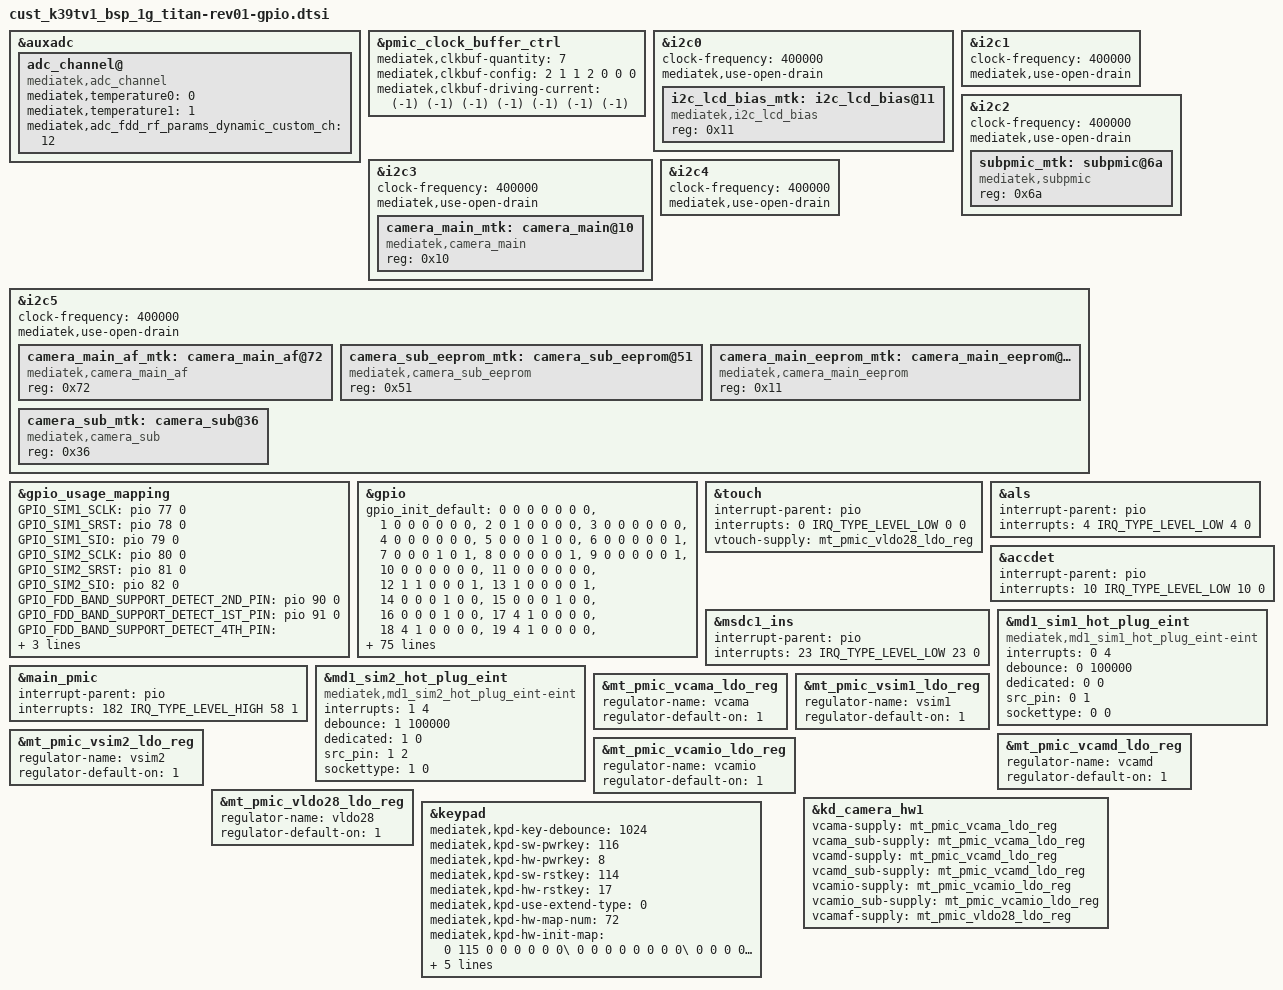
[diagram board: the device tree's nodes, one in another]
/*
 *Copyright (C) 2019 MediaTek Inc.
 *
 *This program is free software: you can redistribute it and/or modify
 *it under the terms of the GNU General Public License version 2 as
 *published by the Free Software Foundation.
 *
 *This program is distributed in the hope that it will be useful,
 *but WITHOUT ANY WARRANTY; without even the implied warranty of
 *MERCHANTABILITY or FITNESS FOR A PARTICULAR PURPOSE. See the
 *GNU General Public License for more details.
 *
 *You should have received a copy of the GNU General Public License
 *along with this program.
 *If not, see <http://www.gnu.org/licenses/>.
 */

/*
 * Generated by MTK SP DrvGen Version: 3.5.160809 for MT6739.
 * 2020-03-31 12:44:13
 * Do Not Modify The File.
 */
/*************************
 * ADC DTSI File
 *************************/

&auxadc {
	adc_channel@ {
		compatible = "mediatek,adc_channel";
		mediatek,temperature0 = <0>;
		mediatek,temperature1 = <1>;
		mediatek,adc_fdd_rf_params_dynamic_custom_ch = <12>;
		status = "okay";
	};
};


/*************************
 * CLK_BUF DTSI File
 *************************/

&pmic_clock_buffer_ctrl {
	mediatek,clkbuf-quantity = <7>;
	mediatek,clkbuf-config = <2 1 1 2 0 0 0>;
	mediatek,clkbuf-driving-current = <(-1) (-1) (-1) (-1) (-1) (-1) (-1)>;
	status = "okay";
};


/*************************
 * I2C DTSI File
 *************************/

&i2c0 {
	#address-cells = <1>;
	#size-cells = <0>;
	clock-frequency = <400000>;
	mediatek,use-open-drain;
	i2c_lcd_bias_mtk:i2c_lcd_bias@11 {
		compatible = "mediatek,i2c_lcd_bias";
		reg = <0x11>;
		status = "okay";
	};

};

&i2c1 {
	#address-cells = <1>;
	#size-cells = <0>;
	clock-frequency = <400000>;
	mediatek,use-open-drain;
};

&i2c2 {
	#address-cells = <1>;
	#size-cells = <0>;
	clock-frequency = <400000>;
	mediatek,use-open-drain;
	subpmic_mtk:subpmic@6a {
		compatible = "mediatek,subpmic";
		reg = <0x6a>;
		status = "okay";
	};

};

&i2c3 {
	#address-cells = <1>;
	#size-cells = <0>;
	clock-frequency = <400000>;
	mediatek,use-open-drain;
	camera_main_mtk:camera_main@10 {
		compatible = "mediatek,camera_main";
		reg = <0x10>;
		status = "okay";
	};

};

&i2c4 {
	#address-cells = <1>;
	#size-cells = <0>;
	clock-frequency = <400000>;
	mediatek,use-open-drain;
};

&i2c5 {
	#address-cells = <1>;
	#size-cells = <0>;
	clock-frequency = <400000>;
	mediatek,use-open-drain;
	camera_main_af_mtk:camera_main_af@72 {
		compatible = "mediatek,camera_main_af";
		reg = <0x72>;
		status = "okay";
	};

	camera_sub_eeprom_mtk:camera_sub_eeprom@51 {
		compatible = "mediatek,camera_sub_eeprom";
		reg = <0x51>;
		status = "okay";
	};

	camera_main_eeprom_mtk:camera_main_eeprom@11 {
		compatible = "mediatek,camera_main_eeprom";
		reg = <0x11>;
		status = "okay";
	};

	camera_sub_mtk:camera_sub@36 {
		compatible = "mediatek,camera_sub";
		reg = <0x36>;
		status = "okay";
	};

};



/*************************
 * GPIO DTSI File
 *************************/

&gpio_usage_mapping {
	GPIO_SIM1_SCLK = <&pio 77 0>;
	GPIO_SIM1_SRST = <&pio 78 0>;
	GPIO_SIM1_SIO = <&pio 79 0>;
	GPIO_SIM2_SCLK = <&pio 80 0>;
	GPIO_SIM2_SRST = <&pio 81 0>;
	GPIO_SIM2_SIO = <&pio 82 0>;
	GPIO_FDD_BAND_SUPPORT_DETECT_2ND_PIN = <&pio 90 0>;
	GPIO_FDD_BAND_SUPPORT_DETECT_1ST_PIN = <&pio 91 0>;
	GPIO_FDD_BAND_SUPPORT_DETECT_4TH_PIN = <&pio 108 0>;
	GPIO_FDD_BAND_SUPPORT_DETECT_3RD_PIN = <&pio 112 0>;
};

&gpio{
	gpio_init_default = <0 0 0 0 0 0 0>,
		<1 0 0 0 0 0 0>,
		<2 0 1 0 0 0 0>,
		<3 0 0 0 0 0 0>,
		<4 0 0 0 0 0 0>,
		<5 0 0 0 1 0 0>,
		<6 0 0 0 0 0 1>,
		<7 0 0 0 1 0 1>,
		<8 0 0 0 0 0 1>,
		<9 0 0 0 0 0 1>,
		<10 0 0 0 0 0 0>,
		<11 0 0 0 0 0 0>,
		<12 1 1 0 0 0 1>,
		<13 1 0 0 0 0 1>,
		<14 0 0 0 1 0 0>,
		<15 0 0 0 1 0 0>,
		<16 0 0 0 1 0 0>,
		<17 4 1 0 0 0 0>,
		<18 4 1 0 0 0 0>,
		<19 4 1 0 0 0 0>,
		<20 1 0 0 1 1 0>,
		<21 1 0 0 1 0 0>,
		<22 0 0 0 1 0 0>,
		<23 0 0 0 0 0 0>,
		<24 1 1 0 1 0 0>,
		<25 0 1 0 0 0 0>,
		<26 0 1 0 0 0 0>,
		<27 0 1 0 1 1 0>,
		<28 0 0 0 0 0 0>,
		<29 0 1 0 0 0 0>,
		<30 0 1 0 0 0 0>,
		<31 1 0 0 1 0 0>,
		<32 1 0 0 1 0 0>,
		<33 1 0 0 1 0 0>,
		<34 1 0 0 1 0 0>,
		<35 4 0 0 0 0 0>,
		<36 0 0 0 0 0 0>,
		<37 0 0 0 0 0 0>,
		<38 1 0 0 1 1 1>,
		<39 1 0 0 1 0 1>,
		<40 1 1 0 1 0 1>,
		<41 1 0 0 1 1 1>,
		<42 1 0 0 1 1 1>,
		<43 1 0 0 1 1 1>,
		<44 1 0 0 1 1 1>,
		<45 1 0 0 1 1 1>,
		<46 1 0 0 1 1 1>,
		<47 1 0 0 1 1 1>,
		<48 1 0 0 1 1 1>,
		<49 1 1 0 1 1 0>,
		<50 0 0 0 1 0 0>,
		<51 0 0 0 1 0 0>,
		<52 0 0 0 1 0 0>,
		<53 0 0 0 1 0 0>,
		<54 0 0 0 1 0 0>,
		<55 1 1 0 1 0 0>,
		<56 1 1 0 1 0 0>,
		<57 1 1 0 1 0 0>,
		<58 1 0 0 1 0 0>,
		<59 1 1 0 1 0 0>,
		<60 1 1 0 1 0 0>,
		<61 1 1 0 1 0 0>,
		<62 1 1 0 1 0 0>,
		<63 1 1 0 1 0 0>,
		<64 1 1 0 1 0 0>,
		<65 1 1 0 1 0 0>,
		<66 1 0 0 1 0 0>,
		<67 1 0 0 1 0 0>,
		<68 1 0 0 1 0 0>,
		<69 1 0 0 1 0 0>,
		<70 1 0 0 1 0 1>,
		<71 1 1 0 1 1 1>,
		<72 1 1 0 1 0 1>,
		<73 1 0 0 1 1 1>,
		<74 1 0 0 1 1 1>,
		<75 1 0 0 1 1 1>,
		<76 1 0 0 1 1 1>,
		<77 1 1 0 1 0 0>,
		<78 1 1 0 1 0 0>,
		<79 1 0 0 1 1 0>,
		<80 1 1 0 1 0 0>,
		<81 1 1 0 1 0 0>,
		<82 1 0 0 1 1 0>,
		<83 1 1 0 1 0 0>,
		<84 0 0 0 1 0 0>,
		<85 0 0 0 1 0 0>,
		<86 0 0 0 1 0 0>,
		<87 0 0 0 1 0 0>,
		<88 1 0 0 1 0 0>,
		<89 1 0 0 1 0 0>,
		<90 0 0 0 1 0 0>,
		<91 0 0 0 1 0 0>,
		<92 1 1 0 1 0 0>,
		<93 1 1 0 1 0 0>,
		<94 0 0 0 0 0 0>,
		<95 1 0 0 0 0 0>,
		<96 0 1 0 0 0 0>,
		<97 1 1 0 1 0 0>,
		<98 1 1 0 1 0 0>,
		<99 0 0 0 1 0 0>,
		<100 1 1 0 1 0 0>,
		<101 1 1 0 1 0 0>,
		<102 1 1 0 1 0 0>,
		<103 0 0 0 1 0 0>,
		<104 0 0 0 1 0 0>,
		<105 1 1 0 1 0 0>,
		<106 1 1 0 1 0 0>,
		<107 1 1 0 1 0 0>,
		<108 0 0 0 0 0 0>,
		<109 1 1 0 1 0 0>,
		<110 0 0 0 1 0 0>,
		<111 0 0 0 1 0 0>,
		<112 0 0 0 1 0 0>,
		<113 1 0 0 1 0 0>,
		<114 1 0 0 1 0 0>,
		<115 1 0 0 1 0 0>,
		<116 1 0 0 1 0 0>,
		<117 0 1 0 0 0 0>,
		<118 0 0 0 1 0 0>,
		<119 0 1 0 0 0 0>,
		<120 1 0 0 1 1 1>,
		<121 1 0 0 1 1 1>,
		<122 0 1 0 0 0 1>,
		<123 3 0 0 0 0 0>,
		<124 3 0 0 0 0 0>,
		<125 0 1 0 0 0 0>,
		<126 1 0 0 1 0 0>,
		<127 1 0 0 1 0 0>,
		<128 1 0 0 1 1 0>,
		<129 1 0 0 1 1 0>,
		<130 1 0 0 1 1 0>,
		<131 1 0 0 1 1 0>,
		<132 1 0 0 1 1 0>,
		<133 1 0 0 1 1 0>,
		<134 1 0 0 1 1 0>,
		<135 1 0 0 1 1 0>,
		<136 0 1 0 0 0 0>,
		<137 1 0 0 1 0 0>,
		<138 1 0 0 1 0 0>,
		<139 1 0 0 1 0 0>,
		<140 1 0 0 1 0 0>,
		<141 1 0 0 1 0 0>,
		<142 1 0 0 1 0 0>,
		<143 1 0 0 1 0 0>,
		<144 1 1 0 1 0 0>,
		<145 1 1 0 1 0 0>,
		<146 1 0 0 1 0 0>,
		<147 1 1 0 1 0 0>,
		<148 1 0 0 1 0 0>,
		<149 1 0 0 1 0 0>,
		<150 1 0 0 1 0 0>,
		<151 1 0 0 1 0 0>,
		<152 1 0 0 1 0 0>,
		<153 1 0 0 1 0 0>,
		<154 1 0 0 1 0 0>,
		<155 1 0 0 1 0 0>,
		<156 1 0 0 1 0 0>,
		<157 1 0 0 1 0 0>,
		<158 1 0 0 1 0 0>,
		<159 1 0 0 1 0 0>,
		<160 0 0 0 1 0 0>,
		<161 0 0 0 1 0 0>,
		<162 0 0 0 1 0 0>,
		<163 0 0 0 1 0 0>,
		<164 0 0 0 1 0 0>,
		<165 0 0 0 1 0 0>,
		<166 0 0 0 1 0 0>,
		<167 0 0 0 1 0 0>,
		<168 0 0 0 1 0 0>;
};


/*************************
 * EINT DTSI File
 *************************/

#include <dt-bindings/interrupt-controller/irq.h>
#include <dt-bindings/interrupt-controller/arm-gic.h>

&touch {
	interrupt-parent = <&pio>;
	interrupts = <0 IRQ_TYPE_LEVEL_LOW 0 0>;
	status = "okay";
};

&als {
	interrupt-parent = <&pio>;
	interrupts = <4 IRQ_TYPE_LEVEL_LOW 4 0>;
	status = "okay";
};

&accdet {
	interrupt-parent = <&pio>;
	interrupts = <10 IRQ_TYPE_LEVEL_LOW 10 0>;
	status = "okay";
};

&msdc1_ins {
	interrupt-parent = <&pio>;
	interrupts = <23 IRQ_TYPE_LEVEL_LOW 23 0>;
	status = "okay";
};

&main_pmic {
	interrupt-parent = <&pio>;
	interrupts = <182 IRQ_TYPE_LEVEL_HIGH 58 1>;
	status = "okay";
};



/*************************
 * MD1_EINT DTSI File
 *************************/

&md1_sim1_hot_plug_eint {
	compatible = "mediatek,md1_sim1_hot_plug_eint-eint";
	interrupts = <0 4>;
	debounce = <0 100000>;
	dedicated = <0 0>;
	src_pin = <0 1>;
	sockettype = <0 0>;
	status = "okay";
};

&md1_sim2_hot_plug_eint {
	compatible = "mediatek,md1_sim2_hot_plug_eint-eint";
	interrupts = <1 4>;
	debounce = <1 100000>;
	dedicated = <1 0>;
	src_pin = <1 2>;
	sockettype = <1 0>;
	status = "okay";
};



/*************************
 * PMIC DTSI File
 *************************/

&mt_pmic_vcama_ldo_reg {
	regulator-name = "vcama";
	regulator-default-on = <1>; /* 0:skip, 1: off, 2:on */
	status = "okay";
};
&mt_pmic_vsim1_ldo_reg {
	regulator-name = "vsim1";
	regulator-default-on = <1>; /* 0:skip, 1: off, 2:on */
	status = "okay";
};
&mt_pmic_vsim2_ldo_reg {
	regulator-name = "vsim2";
	regulator-default-on = <1>; /* 0:skip, 1: off, 2:on */
	status = "okay";
};
&mt_pmic_vcamd_ldo_reg {
	regulator-name = "vcamd";
	regulator-default-on = <1>; /* 0:skip, 1: off, 2:on */
	status = "okay";
};
&mt_pmic_vcamio_ldo_reg {
	regulator-name = "vcamio";
	regulator-default-on = <1>; /* 0:skip, 1: off, 2:on */
	status = "okay";
};
&mt_pmic_vldo28_ldo_reg {
	regulator-name = "vldo28";
	regulator-default-on = <1>; /* 0:skip, 1: off, 2:on */
	status = "okay";
};

&kd_camera_hw1 {
	vcama-supply = <&mt_pmic_vcama_ldo_reg>;
	vcama_sub-supply = <&mt_pmic_vcama_ldo_reg>;
	vcamd-supply = <&mt_pmic_vcamd_ldo_reg>;
	vcamd_sub-supply = <&mt_pmic_vcamd_ldo_reg>;
	vcamio-supply = <&mt_pmic_vcamio_ldo_reg>;
	vcamio_sub-supply = <&mt_pmic_vcamio_ldo_reg>;
	vcamaf-supply = <&mt_pmic_vldo28_ldo_reg>;
	status = "okay";
};

&touch {
	vtouch-supply = <&mt_pmic_vldo28_ldo_reg>;
	status = "okay";
};


/*************************
 * POWER DTSI File
 *************************/



/*************************
 * KPD DTSI File
 *************************/

&keypad {
	mediatek,kpd-key-debounce = <1024>;
	mediatek,kpd-sw-pwrkey = <116>;
	mediatek,kpd-hw-pwrkey = <8>;
	mediatek,kpd-sw-rstkey  = <114>;
	mediatek,kpd-hw-rstkey = <17>;
	mediatek,kpd-use-extend-type = <0>;
	/*HW Keycode [0~71] -> Linux Keycode*/
	mediatek,kpd-hw-map-num = <72>;
	mediatek,kpd-hw-init-map = <0 115 0 0 0 0 0 0\
		0 0 0 0 0 0 0 0\
		0 0 0 0 0 0 0 0\
		0 0 0 0 0 0 0 0\
		0 0 0 0 0 0 0 0\
		0 0 0 0 0 0 0 0\
		0 0 0 0 0 0 0 0\
		0 0 0 0 0 0 0 0\
		0 0 0 0 0 0 0 0>;
	mediatek,kpd-pwrkey-eint-gpio = <0>;
	mediatek,kpd-pwkey-gpio-din  = <0>;
	mediatek,kpd-hw-dl-key2 = <8>;
	mediatek,kpd-hw-recovery-key = <17>;
	mediatek,kpd-hw-factory-key = <1>;
	status = "okay";
};


